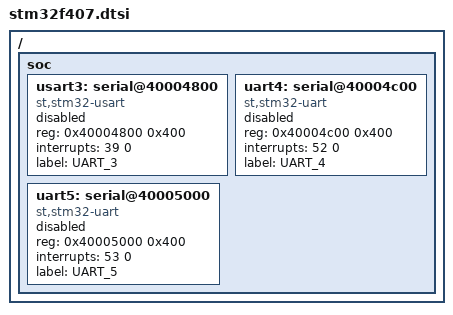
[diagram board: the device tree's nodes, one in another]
/*
 * Copyright (c) 2017 Linaro Limited
 *
 * SPDX-License-Identifier: Apache-2.0
 */

#include <st/stm32f411.dtsi>

/ {
	soc {
		usart3: serial@40004800 {
			compatible = "st,stm32-usart", "st,stm32-uart";
			reg = <0x40004800 0x400>;
			interrupts = <39 0>;
			status = "disabled";
			label = "UART_3";
		};

		uart4: serial@40004c00 {
			compatible ="st,stm32-uart";
			reg = <0x40004c00 0x400>;
			interrupts = <52 0>;
			status = "disabled";
			label = "UART_4";
		};

		uart5: serial@40005000 {
			compatible = "st,stm32-uart";
			reg = <0x40005000 0x400>;
			interrupts = <53 0>;
			status = "disabled";
			label = "UART_5";
		};
	};
};
